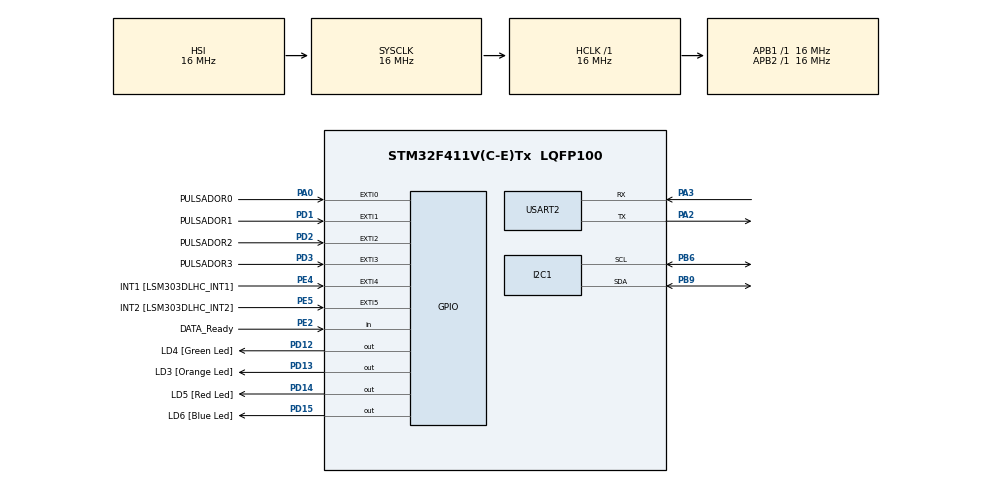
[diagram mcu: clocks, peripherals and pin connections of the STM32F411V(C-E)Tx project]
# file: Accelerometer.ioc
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FREERTOS.Tasks01=defaultTask,24,4096,StartDefaultTask,Default,NULL,Dynamic,NULL,NULL
FREERTOS.configMINIMAL_STACK_SIZE=4096
FREERTOS.configTOTAL_HEAP_SIZE=32768
Mcu.Family=STM32F4
Mcu.Name=STM32F411V(C-E)Tx
Mcu.Package=LQFP100
NVIC.EXTI0_IRQn=true\:5\:0\:false\:false\:true\:true\:true\:true
NVIC.EXTI1_IRQn=true\:5\:0\:false\:false\:true\:true\:true\:true
NVIC.EXTI2_IRQn=true\:5\:0\:false\:false\:true\:true\:true\:true
NVIC.EXTI3_IRQn=true\:5\:0\:false\:false\:true\:true\:true\:true
NVIC.PriorityGroup=NVIC_PRIORITYGROUP_4
NVIC.TIM1_UP_TIM10_IRQn=true\:0\:0\:false\:false\:true\:false\:false\:true
NVIC.TimeBase=TIM1_UP_TIM10_IRQn
NVIC.TimeBaseIP=TIM1
PA0-WKUP.GPIO_Label=PULSADOR0
PA0-WKUP.Signal=GPXTI0
PA13.Mode=Serial_Wire
PA13.Signal=SYS_JTMS-SWDIO
PA14.Mode=Serial_Wire
PA14.Signal=SYS_JTCK-SWCLK
PA2.Mode=Asynchronous
PA2.Signal=USART2_TX
PA3.Mode=Asynchronous
PA3.Signal=USART2_RX
PB6.Mode=I2C
PB6.Signal=I2C1_SCL
PB9.Mode=I2C
PB9.Signal=I2C1_SDA
PC14-OSC32_IN.Mode=LSE-External-Oscillator
PC14-OSC32_IN.Signal=RCC_OSC32_IN
PC15-OSC32_OUT.Mode=LSE-External-Oscillator
PC15-OSC32_OUT.Signal=RCC_OSC32_OUT
PD1.GPIO_Label=PULSADOR1
PD1.GPIO_PuPd=GPIO_PULLDOWN
PD1.Signal=GPXTI1
PD12.GPIO_Label=LD4 [Green Led]
PD12.Signal=GPIO_Output
PD13.GPIO_Label=LD3 [Orange Led]
PD13.Signal=GPIO_Output
PD14.GPIO_Label=LD5 [Red Led]
PD14.Signal=GPIO_Output
PD15.GPIO_Label=LD6 [Blue Led]
PD15.Signal=GPIO_Output
PD2.GPIO_Label=PULSADOR2
PD2.GPIO_PuPd=GPIO_PULLDOWN
PD2.Signal=GPXTI2
PD3.GPIO_Label=PULSADOR3
PD3.GPIO_PuPd=GPIO_PULLDOWN
PD3.Signal=GPXTI3
PE2.GPIO_Label=DATA_Ready
PE2.Signal=GPIO_Input
PE4.GPIO_Label=INT1 [LSM303DLHC_INT1]
PE4.Signal=GPXTI4
PE5.GPIO_Label=INT2 [LSM303DLHC_INT2]
PE5.Signal=GPXTI5
PH0\ -\ OSC_IN.Mode=HSE-External-Clock-Source
PH0\ -\ OSC_IN.Signal=RCC_OSC_IN
PH1\ -\ OSC_OUT.Mode=HSE-External-Clock-Source
PH1\ -\ OSC_OUT.Signal=RCC_OSC_OUT
ProjectManager.HeapSize=0x200
ProjectManager.StackSize=0x400
ProjectManager.TargetToolchain=STM32CubeIDE
RCC.AHBFreq_Value=16000000
RCC.APB1Freq_Value=16000000
RCC.APB2Freq_Value=16000000
RCC.CortexFreq_Value=16000000
RCC.HSE_VALUE=25000000
RCC.HSI_VALUE=16000000
RCC.SYSCLKFreq_VALUE=16000000
RCC.VCOOutputFreq_Value=192000000
USART2.VirtualMode=VM_ASYNC
VP_FREERTOS_VS_CMSIS_V2.Mode=CMSIS_V2
VP_SYS_VS_tim1.Mode=TIM1
board=custom

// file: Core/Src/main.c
/* USER CODE BEGIN Header */
/**
  ******************************************************************************
  * @file           : main.c
  * @brief          : Main program body
  ******************************************************************************
  * @attention
  *
  * <h2><center>&copy; Copyright (c) 2019 STMicroelectronics.
  * All rights reserved.</center></h2>
  *
  * This software component is licensed by ST under BSD 3-Clause license,
  * the "License"; You may not use this file except in compliance with the
  * License. You may obtain a copy of the License at:
  *                        opensource.org/licenses/BSD-3-Clause
  *
  ******************************************************************************
  */
/* USER CODE END Header */

#include "main.h"
#include "cmsis_os.h"

/* USER CODE BEGIN Includes */
#include "key_rtos.h"
#include "stdio.h"
#include "accelerometer_rtos.h"
/* USER CODE END Includes */

I2C_HandleTypeDef hi2c1;

UART_HandleTypeDef huart2;

osThreadId_t defaultTaskHandle;

void SystemClock_Config(void);
static void MX_GPIO_Init(void);
static void MX_I2C1_Init(void);
static void MX_USART2_UART_Init(void);
void StartDefaultTask(void *argument);

int main(void)
{

  /* MCU Configuration--------------------------------------------------------*/

  /* Reset of all peripherals, Initializes the Flash interface and the Systick. */
  HAL_Init();

  /* Configure the system clock */
  SystemClock_Config();

  /* Initialize all configured peripherals */
  MX_GPIO_Init();
  MX_I2C1_Init();
  MX_USART2_UART_Init();

  osKernelInitialize();

  /* Create the thread(s) */
  /* definition and creation of defaultTask */
  const osThreadAttr_t defaultTask_attributes = {
    .name = "defaultTask",
    .priority = (osPriority_t) osPriorityNormal,
    .stack_size = 4096
  };
  defaultTaskHandle = osThreadNew(StartDefaultTask, NULL, &defaultTask_attributes);

  /* USER CODE BEGIN RTOS_THREADS */
  /* add threads, ... */
  Init_Events(); //inicializacion de evento pulsador
  //Accelerometer_Init();
  /* USER CODE END RTOS_THREADS */

  /* Start scheduler */
  osKernelStart();

  /* We should never get here as control is now taken by the scheduler */

  /* Infinite loop */
  while (1)
  {

  }
}

void SystemClock_Config(void)
{
  RCC_OscInitTypeDef RCC_OscInitStruct = {0};
  RCC_ClkInitTypeDef RCC_ClkInitStruct = {0};

  /** Configure the main internal regulator output voltage
  */
  __HAL_RCC_PWR_CLK_ENABLE();
  __HAL_PWR_VOLTAGESCALING_CONFIG(PWR_REGULATOR_VOLTAGE_SCALE1);
  /** Initializes the CPU, AHB and APB busses clocks
  */
  RCC_OscInitStruct.OscillatorType = RCC_OSCILLATORTYPE_HSI;
  RCC_OscInitStruct.HSIState = RCC_HSI_ON;
  RCC_OscInitStruct.HSICalibrationValue = RCC_HSICALIBRATION_DEFAULT;
  RCC_OscInitStruct.PLL.PLLState = RCC_PLL_NONE;
  if (HAL_RCC_OscConfig(&RCC_OscInitStruct) != HAL_OK)
  {
    Error_Handler();
  }
  /** Initializes the CPU, AHB and APB busses clocks
  */
  RCC_ClkInitStruct.ClockType = RCC_CLOCKTYPE_HCLK|RCC_CLOCKTYPE_SYSCLK
                              |RCC_CLOCKTYPE_PCLK1|RCC_CLOCKTYPE_PCLK2;
  RCC_ClkInitStruct.SYSCLKSource = RCC_SYSCLKSOURCE_HSI;
  RCC_ClkInitStruct.AHBCLKDivider = RCC_SYSCLK_DIV1;
  RCC_ClkInitStruct.APB1CLKDivider = RCC_HCLK_DIV1;
  RCC_ClkInitStruct.APB2CLKDivider = RCC_HCLK_DIV1;

  if (HAL_RCC_ClockConfig(&RCC_ClkInitStruct, FLASH_LATENCY_0) != HAL_OK)
  {
    Error_Handler();
  }
}

static void MX_I2C1_Init(void)
{

  hi2c1.Instance = I2C1;
  hi2c1.Init.ClockSpeed = 100000;
  hi2c1.Init.DutyCycle = I2C_DUTYCYCLE_2;
  hi2c1.Init.OwnAddress1 = 0;
  hi2c1.Init.AddressingMode = I2C_ADDRESSINGMODE_7BIT;
  hi2c1.Init.DualAddressMode = I2C_DUALADDRESS_DISABLE;
  hi2c1.Init.OwnAddress2 = 0;
  hi2c1.Init.GeneralCallMode = I2C_GENERALCALL_DISABLE;
  hi2c1.Init.NoStretchMode = I2C_NOSTRETCH_DISABLE;
  if (HAL_I2C_Init(&hi2c1) != HAL_OK)
  {
    Error_Handler();
  }

}

static void MX_USART2_UART_Init(void)
{

  huart2.Instance = USART2;
  huart2.Init.BaudRate = 115200;
  huart2.Init.WordLength = UART_WORDLENGTH_8B;
  huart2.Init.StopBits = UART_STOPBITS_1;
  huart2.Init.Parity = UART_PARITY_NONE;
  huart2.Init.Mode = UART_MODE_TX_RX;
  huart2.Init.HwFlowCtl = UART_HWCONTROL_NONE;
  huart2.Init.OverSampling = UART_OVERSAMPLING_16;
  if (HAL_UART_Init(&huart2) != HAL_OK)
  {
    Error_Handler();
  }

}

static void MX_GPIO_Init(void)
{
  GPIO_InitTypeDef GPIO_InitStruct = {0};

  /* GPIO Ports Clock Enable */
  __HAL_RCC_GPIOE_CLK_ENABLE();
  __HAL_RCC_GPIOC_CLK_ENABLE();
  __HAL_RCC_GPIOH_CLK_ENABLE();
  __HAL_RCC_GPIOA_CLK_ENABLE();
  __HAL_RCC_GPIOD_CLK_ENABLE();
  __HAL_RCC_GPIOB_CLK_ENABLE();

  /*Configure GPIO pin Output Level */
  HAL_GPIO_WritePin(GPIOD, LD4_Pin|LD3_Pin|LD5_Pin|LD6_Pin, GPIO_PIN_RESET);

  /*Configure GPIO pin : DATA_Ready_Pin */
  GPIO_InitStruct.Pin = DATA_Ready_Pin;
  GPIO_InitStruct.Mode = GPIO_MODE_INPUT;
  GPIO_InitStruct.Pull = GPIO_NOPULL;
  HAL_GPIO_Init(DATA_Ready_GPIO_Port, &GPIO_InitStruct);

  /*Configure GPIO pins : INT1_Pin INT2_Pin */
  GPIO_InitStruct.Pin = INT1_Pin|INT2_Pin;
  GPIO_InitStruct.Mode = GPIO_MODE_IT_RISING;
  GPIO_InitStruct.Pull = GPIO_NOPULL;
  HAL_GPIO_Init(GPIOE, &GPIO_InitStruct);

  /*Configure GPIO pin : PULSADOR0_Pin */
  GPIO_InitStruct.Pin = PULSADOR0_Pin;
  GPIO_InitStruct.Mode = GPIO_MODE_IT_RISING;
  GPIO_InitStruct.Pull = GPIO_NOPULL;
  HAL_GPIO_Init(PULSADOR0_GPIO_Port, &GPIO_InitStruct);

  /*Configure GPIO pins : LD4_Pin LD3_Pin LD5_Pin LD6_Pin */
  GPIO_InitStruct.Pin = LD4_Pin|LD3_Pin|LD5_Pin|LD6_Pin;
  GPIO_InitStruct.Mode = GPIO_MODE_OUTPUT_PP;
  GPIO_InitStruct.Pull = GPIO_NOPULL;
  GPIO_InitStruct.Speed = GPIO_SPEED_FREQ_LOW;
  HAL_GPIO_Init(GPIOD, &GPIO_InitStruct);

  /*Configure GPIO pins : PULSADOR1_Pin PULSADOR2_Pin PULSADOR3_Pin */
  GPIO_InitStruct.Pin = PULSADOR1_Pin|PULSADOR2_Pin|PULSADOR3_Pin;
  GPIO_InitStruct.Mode = GPIO_MODE_IT_RISING;
  GPIO_InitStruct.Pull = GPIO_PULLDOWN;
  HAL_GPIO_Init(GPIOD, &GPIO_InitStruct);

  /* EXTI interrupt init*/
  HAL_NVIC_SetPriority(EXTI0_IRQn, 5, 0);
  HAL_NVIC_EnableIRQ(EXTI0_IRQn);

  HAL_NVIC_SetPriority(EXTI1_IRQn, 5, 0);
  HAL_NVIC_EnableIRQ(EXTI1_IRQn);

  HAL_NVIC_SetPriority(EXTI2_IRQn, 5, 0);
  HAL_NVIC_EnableIRQ(EXTI2_IRQn);

  HAL_NVIC_SetPriority(EXTI3_IRQn, 5, 0);
  HAL_NVIC_EnableIRQ(EXTI3_IRQn);

}

void StartDefaultTask(void *argument)
{
  /* USER CODE BEGIN 5 */
  /* Infinite loop */
  for(;;)
  {
	  HAL_GPIO_TogglePin(LD6_GPIO_Port, LD6_Pin);
    osDelay(500);
  }
  /* USER CODE END 5 */
}

void HAL_TIM_PeriodElapsedCallback(TIM_HandleTypeDef *htim)
{
  if (htim->Instance == TIM1) {
    HAL_IncTick();
  }
}

void Error_Handler(void)
{
}

/************************ (C) COPYRIGHT STMicroelectronics *****END OF FILE****/
